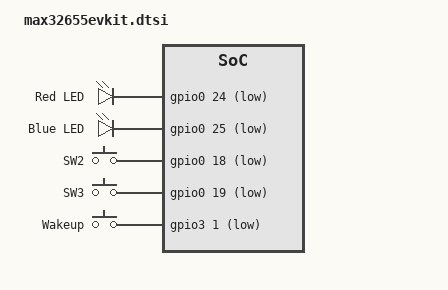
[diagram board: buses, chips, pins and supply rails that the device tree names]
/*
 * Copyright (c) 2023-2026 Analog Devices, Inc.
 *
 * SPDX-License-Identifier: Apache-2.0
 */

#include <adi/max32/max32655-pinctrl.dtsi>
#include <zephyr/dt-bindings/gpio/adi-max32-gpio.h>
#include <zephyr/dt-bindings/input/input-event-codes.h>

/ {
	soc {
		/*
		 * Concatenate SRAM0(32KB) + SRAM1(32KB) for the M4
		 */
		m4_sram: memory@20000000 {
			compatible = "mmio-sram";
			reg = <0x20000000 DT_SIZE_K(64)>;
		};

		/*
		 * Use SRAM2(48KB) + SRAM3(16KB) for the RV32
		 */
		rv32_sram: memory@20010000 {
			compatible = "mmio-sram";
			reg = <0x20010000 DT_SIZE_K(64)>;
		};
	};

	leds {
		compatible = "gpio-leds";

		led1: led_1 {
			gpios = <&gpio0 24 GPIO_ACTIVE_LOW>;
			label = "Red LED";
		};

		led2: led_2 {
			gpios = <&gpio0 25 GPIO_ACTIVE_LOW>;
			label = "Blue LED";
		};
	};

	buttons {
		compatible = "gpio-keys";

		pb1: pb1 {
			gpios = <&gpio0 18 (GPIO_PULL_UP | GPIO_ACTIVE_LOW)>;
			label = "SW2";
			zephyr,code = <INPUT_KEY_0>;
		};

		pb2: pb2 {
			gpios = <&gpio0 19 (GPIO_PULL_UP | GPIO_ACTIVE_LOW)>;
			label = "SW3";
			zephyr,code = <INPUT_KEY_1>;
		};

		pb_wakeup: pb_wakeup {
			gpios = <&gpio3 1
				 (GPIO_PULL_UP | GPIO_ACTIVE_LOW | MAX32_GPIO_VSEL_VDDIOH)>;
			label = "Wakeup";
			zephyr,code = <INPUT_KEY_WAKEUP>;
		};
	};

	/* These aliases are provided for compatibility with samples */
	aliases {
		led0 = &led1;
		led1 = &led2;
		sw0 = &pb1;
		sw1 = &pb2;
		watchdog0 = &wdt0;
	};
};

&clk_ipo {
	status = "okay";
};

&clk_ibro {
	status = "okay";
};

&flash0 {
	partitions {
		compatible = "fixed-partitions";
		#address-cells = <1>;
		#size-cells = <1>;
		ranges;

		m4_partition: partition@0 {
			label = "image-m4";
			reg = <0x0 DT_SIZE_K(352)>;
		};

		storage_partition: partition@58000 {
			label = "storage-m4";
			reg = <0x58000 DT_SIZE_K(32)>;
		};

		rv32_partition: partition@60000 {
			label = "image-rv32";
			reg = <0x60000 DT_SIZE_K(128)>;
		};
	};
};
